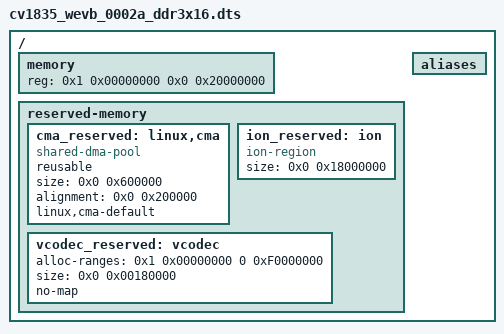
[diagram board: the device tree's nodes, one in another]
#include "cv1835_asic.dtsi"

/ {
	memory {
		reg = <0x1 0x00000000 0x0 0x20000000>; // 512MB
		device_type = "memory";
	};

	reserved-memory {
	  #size-cells = <0x2>;
	  #address-cells = <0x2>;
	  ranges;

		cma_reserved: linux,cma {
			compatible = "shared-dma-pool";
			reusable;
			size = <0x0 0x600000>; // 6MB
			alignment = <0x0 0x200000>; // 2MB
			linux,cma-default;
		};

		ion_reserved: ion {
			compatible = "ion-region";
			size = <0x0 0x18000000>; //288MB + vip 96MB
		};

		vcodec_reserved: vcodec {
			alloc-ranges = <0x1 0x00000000 0 0xF0000000>;
			size = <0x0 0x00180000>; // 1.5MB
			no-map;
		};
	};

	/delete-node/ cvi-spif@10000000;
	/delete-node/ cv-spinf@4060000;
	/delete-node/ wifi-sd@4320000;
	/delete-node/ i2c@04010000;
	/delete-node/ i2c@04020000;
	/delete-node/ ethernet@04520000;
	/delete-node/ i2s@04110000;
	/delete-node/ i2s@04120000;
	/delete-node/ sound_ext1;
	/delete-node/ sound_ext2;
	/delete-node/ dummy_card;
	/delete-node/ sound_PDM;

	aliases {
		/delete-property/ ethernet1;
	};
};

